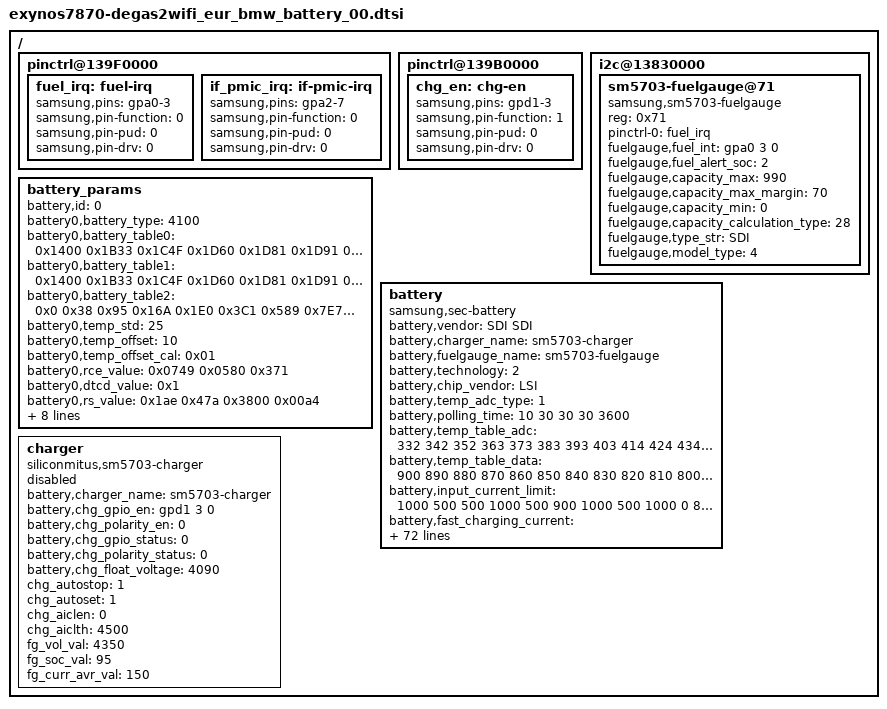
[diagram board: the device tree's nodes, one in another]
/*
 * SAMSUNG UNIVERSAL5433 board device tree source
 *
 * Copyright (c) 2015 Samsung Electronics Co., Ltd.
 *		http://www.samsung.com
 *
 * This program is free software; you can redistribute it and/or modify
 * it under the terms of the GNU General Public License version 2 as
 * published by the Free Software Foundation.
*/

/ {
	pinctrl@139F0000 {
		fuel_irq: fuel-irq {
			samsung,pins = "gpa0-3";
			samsung,pin-function = <0>;
			samsung,pin-pud = <0>;
			samsung,pin-drv = <0>;
		};
	};

	pinctrl@139F0000 {
		if_pmic_irq: if-pmic-irq {
			samsung,pins = "gpa2-7";
			samsung,pin-function = <0>;
			samsung,pin-pud = <0>;
			samsung,pin-drv = <0>;
		};
	};

	pinctrl@139B0000 {
		chg_en: chg-en {
			samsung,pins = "gpd1-3";
			samsung,pin-function = <1>;
			samsung,pin-pud = <0>;
			samsung,pin-drv = <0>;
		};
	};

	i2c@13830000 {
		status = "okay";
		sm5703-fuelgauge@71 {
			compatible = "samsung,sm5703-fuelgauge";
			reg = <0x71>;
			pinctrl-names = "default";
			pinctrl-0 = <&fuel_irq>;
			fuelgauge,fuel_int = <&gpa0 3 0>;
			fuelgauge,fuel_alert_soc = <2>;
			fuelgauge,capacity_max = <990>;
			fuelgauge,capacity_max_margin = <70>;
			fuelgauge,capacity_min = <0>;
			fuelgauge,capacity_calculation_type = <28>;
			fuelgauge,type_str = "SDI";
			fuelgauge,model_type = <4>;
		};
	};

	battery_params {
		battery,id = <0>; /* -1 means auto, detected by F/G */
		battery0,battery_type = <4100>; /* 4200 4350 4400 */
		battery0,battery_table0 = <0x1400 0x1B33 0x1C4F 0x1D60 0x1D81 0x1D91 0x1DE2 0x1E1F 0x1E64 0x1E96 0x1EE2 0x1F3C 0x1FA8 0x1FFF 0x207F 0x2133>;
		battery0,battery_table1 = <0x1400 0x1B33 0x1C4F 0x1D60 0x1D81 0x1D91 0x1DE2 0x1E1F 0x1E64 0x1E96 0x1EE2 0x1F3C 0x1FA8 0x1FFF 0x207F 0x2133>;
		battery0,battery_table2 = <0x0 0x38 0x95 0x16A 0x1E0 0x3C1 0x589 0x7E7 0xC9D 0xEF5 0x1152 0x127E 0x14DC 0x173A 0x1866 0x1879>;
		battery0,temp_std = <25>;
		battery0,temp_offset = <10>;
		battery0,temp_offset_cal = <0x01>;
		battery0,rce_value = <0x0749 0x0580 0x371>;
		battery0,dtcd_value = <0x1>;
		battery0,rs_value = <0x1ae 0x47a 0x3800 0x00a4>; /*rs mix_factor max min*/
		battery0,vit_period = <0x3506>;
		battery0,mix_value = <0x0503 0x0004>; /*mix_rate init_blank*/
		battery0,topoff_soc = <0x0 0x5>; /*enable soc*/
		battery0,tem_poff = <3400 50 3350 50>;
		battery0,charge_offset_cal = <0x00>;
		battery0,volt_cal = <0x809E>;
		battery0,curr_cal = <0x8085>;
		battery0,ext_temp_cal = <0 10 1 1 1 7 1 1>;
	};

	battery {
		status = "okay";

		pinctrl-names = "default";

		compatible = "samsung,sec-battery";
		battery,vendor = "SDI SDI";
		battery,charger_name = "sm5703-charger";
		battery,fuelgauge_name = "sm5703-fuelgauge";
		battery,technology = <2>; /* POWER_SUPPLY_TECHNOLOGY_LION */
		/* .temp_cohot = -1000; */
		/* .temp_cocold = -4325; */

		battery,chip_vendor = "LSI";
		battery,temp_adc_type = <1>; /* SEC_BATTERY_ADC_TYPE_AP */

		battery,polling_time = <10 30 30 30 3600>;

		battery,temp_table_adc = <332 342 352 363 373 383 393 403 414 424 434 450 466 482 498 515 530
					546 561 577 593 610 627 644 661 681 701 722 744 769 794 817 841 856 872
					924 966 1007 1022 1038 1068 1099 1136 1170 1205 1242 1288 1324 1360 1409 1459
					1495 1532 1568 1605 1642 1692 1743 1793 1844 1895 1933 1972 2010 2049 2088 2126
					2165 2203 2242 2281 2317 2353 2389 2425 2461 2509 2557 2605 2653 2702 2734 2767
					2800 2832 2865 2898 2931 2965 2998 3030 3060 3090 3118 3147 3177 3214 3239 3263
					3288 3313 3331 3349 3367 3386 3404 3409 3418 3426 3434 3442>;

		battery,temp_table_data = <900 890 880 870 860 850 840 830 820 810 800 790 780 770 760 750 740 730 720 710 700 690
					   680 670 660 650 640 630 620 610 600 590 580 570 560 550 540 530 520 510 500 490 480 470
					   460 450 440 430 420 410 400 390 380 370 360 350 340 330 320 310 300 290 280 270 260 250
					   240 230 220 210 200 190 180 170 160 150 140 130 120 110 100 90 80 70 60 50 40 30 20 10
					   0 (-10) (-20) (-30) (-40) (-50) (-60) (-70) (-80) (-90) (-100) (-110) (-120) (-130) (-140)
					   (-150) (-160) (-170) (-180) (-190) (-200)>;

		battery,input_current_limit = <1000 500 500 1000 500 900 1000 500 1000 0 820 820 820 1000 1000 0 0 400 700 1000 300 1000 1000 0 1000 1000 1000 1000 80 1000 1000 1000 1000 1000 820 820>;
		battery,fast_charging_current = <1000 0 0 1000 500 1000 1000 500 1000 0 1000 1000 1000 1000 1000 0 0 400 700 1000 300 1000 1000 0 1000 1000 1000 1000 80 1000 1000 1000 0 1000 1000 1000>;
		battery,full_check_current_1st = <200 0 0 200 200 200 200 200 200 0 200 200 200 200 200 0 0 200 200 200 200 200 200 0 200 200 200 200 0 200 200 200 0 200 200 200>;
		battery,full_check_current_2nd = <150 0 0 150 150 150 150 150 150 0 150 150 150 150 150 0 0 150 150 150 150 150 150 0 150 150 150 150 0 150 150 150 0 150 150 150>;

		battery,inbat_voltage = <0>;
		battery,inbat_voltage_table_adc = <3120 3101 3061 3038 3001 2956 2920 2887 2856 2814
						2793 2754 2720 2677 2641 2613 2572 2531 2502 2467 2436>;
		battery,inbat_voltage_table_data = <438 435 430 425 420 415 410 405 400 395
						390 385 380 375 370 365 360 355 350 345 340>;

		battery,adc_check_count = <5>;

		battery,cable_check_type = <4>; /* SEC_BATTERY_CABLE_CHECK_PSY */
		battery,cable_source_type = <1>; /* SEC_BATTERY_CABLE_SOURCE_EXTERNAL */
		battery,polling_type = <1>; /* SEC_BATTERY_MONITOR_ALARM */
		battery,monitor_initial_count = <0>;

		battery,battery_check_type = <0>; /* SEC_BATTERY_CHECK_NONE */
		battery,check_count = <0>;

		battery,check_adc_max = <1440>;
		battery,check_adc_min = <0>;

		battery,ovp_uvlo_check_type = <3>; /* SEC_BATTERY_OVP_UVLO_CHGPOLLING */

		battery,thermal_source = <2>; /* SEC_BATTERY_THERMAL_SOURCE_ADC */

		battery,temp_check_type = <2>; /* SEC_BATTERY_TEMP_CHECK_TEMP */
		battery,temp_check_count = <1>;
		battery,temp_highlimit_threshold_normal = <800>;
		battery,temp_highlimit_recovery_normal = <750>;
		battery,temp_high_threshold_normal = <500>;
		battery,temp_high_recovery_normal = <450>;
		battery,temp_low_threshold_normal = <0>;
		battery,temp_low_recovery_normal = <5>;
		battery,temp_highlimit_threshold_lpm = <800>;
		battery,temp_highlimit_recovery_lpm = <750>;
		battery,temp_high_threshold_lpm = <500>;
		battery,temp_high_recovery_lpm = <450>;
		battery,temp_low_threshold_lpm = <0>;
		battery,temp_low_recovery_lpm = <5>;
		battery,full_check_type = <7>; /* SEC_BATTERY_FULLCHARGED_CHGPSY */
		battery,full_check_type_2nd = <0>; /* SEC_BATTERY_FULLCHARGED_CHGPSY */
		battery,full_check_count = <1>;
		battery,chg_gpio_full_check = <0>;
		battery,chg_polarity_full_check = <1>;

		/* SEC_BATTERY_FULL_CONDITION_SOC |
		   SEC_BATTERY_FULL_CONDITION_NOTIMEFULL |
		   SEC_BATTERY_FULL_CONDITION_VCELL */
		battery,full_condition_type = <13>;
		battery,full_condition_soc = <93>;
		battery,full_condition_vcell = <4000>;

		battery,recharge_check_count = <2>;
		battery,recharge_condition_type = <4>; /* SEC_BATTERY_RECHARGE_CONDITION_VCELL */
		battery,recharge_condition_soc = <98>;
		battery,recharge_condition_vcell = <4050>;

		battery,charging_total_time = <21600>;
		battery,recharging_total_time = <5400>;
		battery,charging_reset_time = <0>;

		battery,always_enable;

		io-channels = <&exynos_adc 1>, <&exynos_adc 3>;
		io-channel-names = "adc-temp", "in-adc-bat";
		#io-channel-cells = <1>;
		io-channel-ranges;

		battery,chg_float_voltage = <4090>;

		battery,self_discharging_en;
		battery,force_discharging_limit = <650>;
		battery,force_discharging_recov = <550>;
		battery,self_discharging_voltage_limit = <4250>;
		battery,discharging_adc_max = <2600>;
		battery,discharging_adc_min = <1700>;
		battery,discharging_ntc_limit = <2750>;

		battery,swelling_high_temp_block = <450>;
		battery,swelling_high_temp_recov = <400>;
		battery,swelling_low_temp_block = <100>;
		battery,swelling_low_temp_recov = <150>;
		battery,swelling_low_temp_current = <1800>;	/* 0.5C */
		battery,swelling_low_temp_topoff = <150>;	/* 0.05C */
		battery,swelling_high_temp_current = <1800>;	/* 0.7C */
		battery,swelling_high_temp_topoff = <150>;	/* 0.05C */
		battery,swelling_drop_float_voltage = <4200>;
		battery,swelling_high_rechg_voltage = <4150>;
		battery,swelling_low_rechg_voltage = <4050>;
	};

	charger {
		status = "disable";
		compatible = "siliconmitus,sm5703-charger";

		/* Charger */
		battery,charger_name = "sm5703-charger";
		battery,chg_gpio_en = <&gpd1 3 0>;
		battery,chg_polarity_en = <0>;
		battery,chg_gpio_status = <0>;
		battery,chg_polarity_status = <0>;
		battery,chg_float_voltage = <4090>;
		chg_autostop = <1>;
		chg_autoset = <1>;
		chg_aiclen = <0>;
		chg_aiclth = <4500>;
		fg_vol_val = <4350>;
		fg_soc_val = <95>;
		fg_curr_avr_val = <150>;
	};
};
